# nrf7140_application register map
Vendor: Nordic Semiconductor; Series: nRF71; File version: 1
CPU: CM33 r0p4, little endian, MPU, FPU, 3 interrupt priority bits, 480 interrupts, 8 SAU regions
Registers are 32-bit, read-write, reset 0x0 unless marked. A register's access mark holds for its fields unless they carry their own. Offsets are from the block's base; [hi:lo] are bit positions; lines under a group give offsets from that group; {n}, {i} and the like mark numbered series; 'fields as' and 'values as' point back to an identical list.

## GLOBAL_GSI_NS (part 1 of 3) — GSI
Base 0x49008000
0x00 TASKS_DMA group — Peripheral tasks.
  0x00 START wo — Start operation.
    [0] START
      1=Trigger task
  0x04 PAUSE wo — Pause operation.
    [0] PAUSE
      1=Trigger task
  0x08 RESET wo — Reset operation.
    [0] RESET
      1=Trigger task
0x100 EVENTS_DSICORE — Event indicating that interrupt triggered at DSI core
  [0] EVENTS_DSICORE
    0=NotGenerated (Event not generated); 1=Generated (Event generated)
0x104 EVENTS_CSICORE — Event indicating that interrupt triggered at CSI core
  [0] EVENTS_CSICORE
    values as EVENTS_DSICORE.EVENTS_DSICORE
0x108 EVENTS_IDIHEADEREN — IDI header data is valid.
  [0] EVENTS_IDIHEADEREN
    values as EVENTS_DSICORE.EVENTS_DSICORE
0x10C EVENTS_DMA group — Peripheral events.
  0x00 EVENTS_DONE group — Peripheral events.
    0x00 LIST — Descriptor list is complete.
      [0] LIST
        values as EVENTS_DSICORE.EVENTS_DSICORE
    0x04 LISTPART — Descriptor list is partially complete. Threshold in CONFIG.LISTPARTTHRESH register has been passed.
      [0] LISTPART
        values as EVENTS_DSICORE.EVENTS_DSICORE
    0x08 SELECTJOB — Selected job is completed. Selection is done via CONFIG.SELECTJOBENABLE.
      [0] SELECTJOB
        values as EVENTS_DSICORE.EVENTS_DSICORE
    0x0C DATA — A job has been completed, i.e. the job's data has been completely transferred either to AXI or DMA bus, depending on direction.
      [0] DATA
        values as EVENTS_DSICORE.EVENTS_DSICORE
    0x10 JOB — A job has been fetched from the joblist.
      [0] JOB
        values as EVENTS_DSICORE.EVENTS_DSICORE
  0x14 ERROR — AXI bus error received.
    [0] ERROR
      values as EVENTS_DSICORE.EVENTS_DSICORE
  0x18 PAUSED — DMA paused with task TASKS_PAUSE.
    [0] PAUSED
      values as EVENTS_DSICORE.EVENTS_DSICORE
  0x1C RESET — DMA reset with task TASKS_RESET.
    [0] RESET
      values as EVENTS_DSICORE.EVENTS_DSICORE
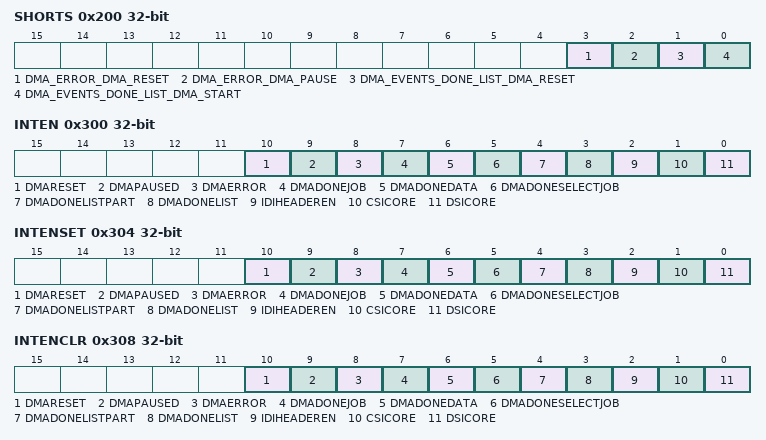
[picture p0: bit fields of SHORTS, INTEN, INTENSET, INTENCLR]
0x200 SHORTS — Shortcuts between local events and tasks
  [all] fields
    0=Disabled (Disable shortcut); 1=Enabled (Enable shortcut)
  [3] DMA_ERROR_DMA_RESET — Shortcut between event DMA.ERROR and task DMA.RESET
  [2] DMA_ERROR_DMA_PAUSE — Shortcut between event DMA.ERROR and task DMA.PAUSE
  [1] DMA_EVENTS_DONE_LIST_DMA_RESET — Shortcut between event DMA.EVENTS_DONE.LIST and task DMA.RESET
  [0] DMA_EVENTS_DONE_LIST_DMA_START — Shortcut between event DMA.EVENTS_DONE.LIST and task DMA.START
0x300 INTEN — Enable or disable interrupt
  [all] fields
    0=Disabled; 1=Enabled
  [10] DMARESET — Enable or disable interrupt for event DMARESET
  [9] DMAPAUSED — Enable or disable interrupt for event DMAPAUSED
  [8] DMAERROR — Enable or disable interrupt for event DMAERROR
  [7] DMADONEJOB — Enable or disable interrupt for event DMADONEJOB
  [6] DMADONEDATA — Enable or disable interrupt for event DMADONEDATA
  [5] DMADONESELECTJOB — Enable or disable interrupt for event DMADONESELECTJOB
  [4] DMADONELISTPART — Enable or disable interrupt for event DMADONELISTPART
  [3] DMADONELIST — Enable or disable interrupt for event DMADONELIST
  [2] IDIHEADEREN — Enable or disable interrupt for event IDIHEADEREN
  [1] CSICORE — Enable or disable interrupt for event CSICORE
  [0] DSICORE — Enable or disable interrupt for event DSICORE
0x304 INTENSET — Enable interrupt
  [all] fields
    on read: 0=Disabled (Read: Disabled); 1=Enabled (Read: Enabled) | on write: 1=Set (Enable)
  [10] DMARESET — Write '1' to enable interrupt for event DMARESET
  [9] DMAPAUSED — Write '1' to enable interrupt for event DMAPAUSED
  [8] DMAERROR — Write '1' to enable interrupt for event DMAERROR
  [7] DMADONEJOB — Write '1' to enable interrupt for event DMADONEJOB
  [6] DMADONEDATA — Write '1' to enable interrupt for event DMADONEDATA
  [5] DMADONESELECTJOB — Write '1' to enable interrupt for event DMADONESELECTJOB
  [4] DMADONELISTPART — Write '1' to enable interrupt for event DMADONELISTPART
  [3] DMADONELIST — Write '1' to enable interrupt for event DMADONELIST
  [2] IDIHEADEREN — Write '1' to enable interrupt for event IDIHEADEREN
  [1] CSICORE — Write '1' to enable interrupt for event CSICORE
  [0] DSICORE — Write '1' to enable interrupt for event DSICORE
0x308 INTENCLR — Disable interrupt
  [all] fields
    on read: 0=Disabled (Read: Disabled); 1=Enabled (Read: Enabled) | on write: 1=Clear (Disable)
  [10] DMARESET — Write '1' to disable interrupt for event DMARESET
  [9] DMAPAUSED — Write '1' to disable interrupt for event DMAPAUSED
  [8] DMAERROR — Write '1' to disable interrupt for event DMAERROR
  [7] DMADONEJOB — Write '1' to disable interrupt for event DMADONEJOB
  [6] DMADONEDATA — Write '1' to disable interrupt for event DMADONEDATA
  [5] DMADONESELECTJOB — Write '1' to disable interrupt for event DMADONESELECTJOB
  [4] DMADONELISTPART — Write '1' to disable interrupt for event DMADONELISTPART
  [3] DMADONELIST — Write '1' to disable interrupt for event DMADONELIST
  [2] IDIHEADEREN — Write '1' to disable interrupt for event IDIHEADEREN
  [1] CSICORE — Write '1' to disable interrupt for event CSICORE
  [0] DSICORE — Write '1' to disable interrupt for event DSICORE
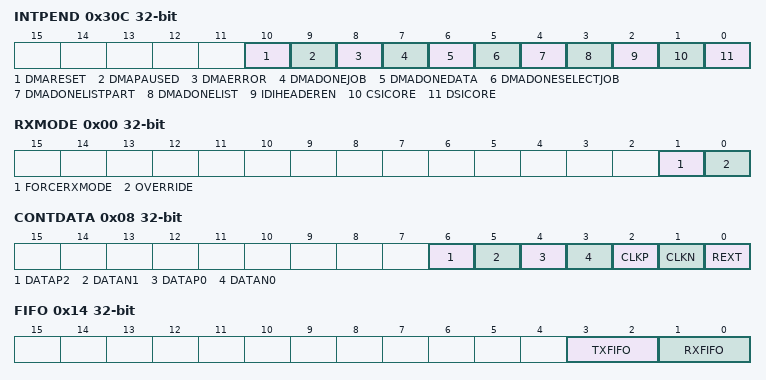
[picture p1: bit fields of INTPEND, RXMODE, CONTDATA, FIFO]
0x30C INTPEND ro — Pending interrupts
  [all] fields
    on read: 0=NotPending (Read: Not pending); 1=Pending (Read: Pending)
  [10] DMARESET — Read pending status of interrupt for event DMARESET
  [9] DMAPAUSED — Read pending status of interrupt for event DMAPAUSED
  [8] DMAERROR — Read pending status of interrupt for event DMAERROR
  [7] DMADONEJOB — Read pending status of interrupt for event DMADONEJOB
  [6] DMADONEDATA — Read pending status of interrupt for event DMADONEDATA
  [5] DMADONESELECTJOB — Read pending status of interrupt for event DMADONESELECTJOB
  [4] DMADONELISTPART — Read pending status of interrupt for event DMADONELISTPART
  [3] DMADONELIST — Read pending status of interrupt for event DMADONELIST
  [2] IDIHEADEREN — Read pending status of interrupt for event IDIHEADEREN
  [1] CSICORE — Read pending status of interrupt for event CSICORE
  [0] DSICORE — Read pending status of interrupt for event DSICORE
0x500 ENABLE — Enable Graphics Serial Interface.
  [0] EN — Enable
    0=Disabled (GSI disabled.); 1=Enabled (GSI enabled.)
0x504 INTERFACE — Select DSI or CSI interface.
  [0] INTERFACE
    0=DSI (DSI interface is selected.); 1=CSI (CSI interface is selected.)
0x508 PLL group — Unspecified
  0x00 SHADOWCONTROL reset 0x1 — Enable direct control of the PLL by the register interface. Otherwise the PLL is controlled by the D-PHY.
    [0] SHADOWCONTROL
      0=REGISTERS (The PLL is controlled by registers.); 1=DPHY (The PLL is controlled by the D-PHY.)
  0x04 MULTIPLICATOR reset 0x28 — Control of the feedback multiplication ratio M.
    [9:0] M — Feedback multiplication ratio
  0x08 DIVISOR reset 0xF — Control of the input frequency division ratio N.
    [3:0] N — frequency division ratio
  0x0C PROPCNTRL — Proportional Charge Pump control
    [5:0] PROPCNTRL
  0x10 INTCNTRL — Integral Charge Pump control
    [5:0] INTCNTRL
  0x14 VCOCNTRL reset 0x3E — VCO operating range, needs to be set appropriately to frequency of operation.
    [5:0] VCOCNTRL
      0=POWERDOWN (Unspecified); 2=FREQ1150MTO1250M (1150 MHz to 1250 MHz); 2=FREQ1110MTO1152M (1100 MHz to 1152 MHz); 5=FREQ630MTO1149M (630 MHz to 1149 MHz); 10=FREQ420MTO660M (420 MHz to 660 MHz); 14=FREQ320MTO440M (320 MHz to 440 MHz); 26=FREQ210MTO330M (210 MHz to 330 MHz); 30=FREQ160MTO220M (160 MHz to 220 MHz); 42=FREQ105MTO165M (105 MHz to 165 MHz); 46=FREQ80MTO110M (80 MHz to 110 MHz); 46=FREQ52M5TO82M5 (52.5 MHz to 82.5 MHz); 62=FREQ40MTO55M (40 MHz to 55 MHz)
  0x18 GMPCNTRL — Controls the effective loop-filter resistance (=1/GMP) to increase/decrease MPLL bandwidth and compensate for change in divider modulus (DIVISOR N).
    [1:0] GMP — 1/GMP = Loop filter resistance
  0x1C CPBIASCNTRL — Charge Pump bias control
    [6:0] CPBIAS
  0x20 LOCK ro — PLL lock indication
    [0] LOCK
      0=NOTLOCKED (PLL is not locked); 1=LOCKED (PLL is locked)
  0x24 FORCELOCK
    [0] FORCELOCK — Force lock indication
      0=DETECTOR (Lock according to lock detector); 1=FORCED (Lock indication forced)
  0x28 CLKSEL — Control of PLL clock output selection. For more information see functional description.
    [1:0] CLKSEL
      0=STOPPED (Clocks stopped); 1=GENERATION (Clocks generation); 2=BUFFERED (Buffered clkext); 3=FORBIDDEN
  0x2C SHADOWCLEAR — Shadow registers clear
    [0] SHADOWCLEAR
      1=CLEAR (Clear shadow registers)
  0x30 UPDATEPLL — Control for PLL operation frequency updated. Write this register to latch PLL control signals from registers to set PLL operating frequency.
    [0] UPDATEPLL
      1=UPDATE (Update PLL control signals from registers.)
0x53C DPHY group — Unspecified
  0x00 RXMODE — In some configurations of the D-PHY the RX mode needs to be overriden by this register.
    [1] FORCERXMODE
      1=ENABLE (Force RX mode.); 0=DISABLE (Do not force RX mode.)
    [0] OVERRIDE — Override the RXMODE signal
      1=ENABLE (Enable override of RXMODE.); 0=DISABLE (Disable override of RXMODE.)
  0x04 CONTEN — This Register places the macro in IO continuity test mode. All other interface signals should be placed in their default values.
    [0] CONTEN
  0x08 CONTDATA ro — Continuity data
    [6] DATAP2, [5] DATAN1, [4] DATAP0, [3] DATAN0, [2] CLKP, [1] CLKN, [0] REXT
  0x0C CFGFREQRANGE — System clock frequency configuration preset. Should be set according to the following equation: cfgclkfreqrange[7:0] = round[(Fcfg_clk(MHz)-17)*4]
    [7:0] CFGFREQRANGE
  0x10 HSFREQRANGE — High-speed Frequency Range Selection.
    [6:0] HSFREQRANGE
  0x14 TESTMODE — Sets the needed signal values for PHY tests
    [0] SHUTDOWNIDDQ
      0=DISABLED (Shutdown IDDQ test mode disabled); 1=ENABLED (IDDQ test mode enabled)
0x554 TESTMUX group — Unspecified
  0x00 TXRXSEL — Select between TX and RX test signal from D-PHY
    [0] TXRXSEL — TX/RX test mux selection
      0=RX (Select RX test signal); 1=TX (Select TX test signal)
0x5A0 IDI group — Unspecified
  0x00 DATATYPE ro — Data type of the IDI packet.
    [5:3] CLASS — Data type class according to the CSI specification.
      0=SYNC (Synchronization short packet data types); 1=GENERICSHORT (Generic short packet data types); 2=GENERICLONG (Generic long packet data types); 3=YUV (YUV data); 4=RGB (RGB data); 5=RAW (RAW data); 6=BYTE (User Defined byte-based data)
    [5:0] DATATYPE — Data type according to the CSI specification. Full type value. See functional description for more details.
    [2:0] SUBTYPE — Data subtype according to the CSI specification. See functional description for more details.
  0x04 WORDCOUNT ro — Number of words in the current packet.
    [15:0] WORDCOUNT
  0x08 ECC ro — Error Correction Code.
    [7:0] ECC
0x600 DMA group — Unspecified
  0x00 STATUS group — EasyVDMA status registers.
    0x00 BYTECOUNT ro — Number of bytes sent or received during processing of current descriptor list
    0x04 ATTRIBUTE ro — Latest job attribute being processed.
      [5:0] ATTRIBUTE
    0x08 ADDRESS ro — Latest address being accessed.
    0x0C JOBCOUNT ro — Number of completed jobs in current descriptor list.
    0x10 BUSERROR ro — AXI bus error status.
      [2:0] BUSERROR — AXI bus error type
        0=NoError (There are no errors.); 1=ReadError (Error related to memory when reading joblist, or error related to memory/register when reading data.); 2=ReadDecodeError (Error related to the joblist address when reading joblist, or error related to address when reading memory/register.); 3=WriteError (Error related to memory/register when writing data.); 4=WriteDecodeError (Error related to the memory/register address when writing data.)
    0x14 FIFO ro — Data fifo status.
      [3:2] TXFIFO — Peripheral-to-Memory direction data fifo status
        0=Empty (Fifo is empty.); 1=NotEmpty (Fifo contains data.); 2=Full (Fifo is full.)
      [1:0] RXFIFO — Memory-to-Peripheral direction data fifo status
        values as TXFIFO
    0x18 ACTIVE ro — DMA activity state.
      [0] ACTIVE
        0=Idle (DMA is in idle state.); 1=Active (Data is being transferred.)
  0x100 CONFIG group — General config registers
    0x00 BUFFERFILL — Data to be used when data is sent with BufferFill attribute
      [7:0] BUFFERFILL
    0x04 LISTPTR — Start address of descriptor list
    0x08 LISTPARTTHRESH — Threshold value for generating event EVENTS_DONE.PARTLIST when descriptor list is partially completed. Value is number of jobs.
      [15:0] LISTPARTTHRESH — Threshold value.
0xF00 PCGCSLAVE group — Unspecified
  {0x0+4j} PENALTY[{j}] (j=0..1) reset 0xFFFFFFFC — Description collection: Penalty level for power/clock pair n. When FULL_PCP_ZERO feature is not supported, PENALTY[0] address overlaps the PENALTY0 address and register description for PENALTY[0] is not valid.
    [1:0] PENALTY — Penalty level
  0x00 PENALTY0 (alternate view of PENALTY[*]) — Penalty level for power/clock pair 0. The register description is valid only when FULL_PCP_ZERO feature is not supported
    [1:0] PENALTY ro — Penalty level
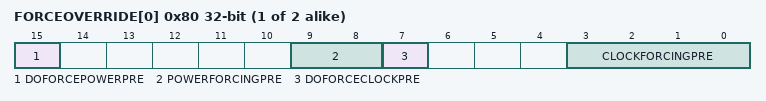
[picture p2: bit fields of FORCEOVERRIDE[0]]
  {0x80+4j} FORCEOVERRIDE[{j}] (j=0..1) — Description collection: Force override of power/clock pair n.
    [15] DOFORCEPOWERPRE, [9:8] POWERFORCINGPRE, [7] DOFORCECLOCKPRE, [3:0] CLOCKFORCINGPRE
